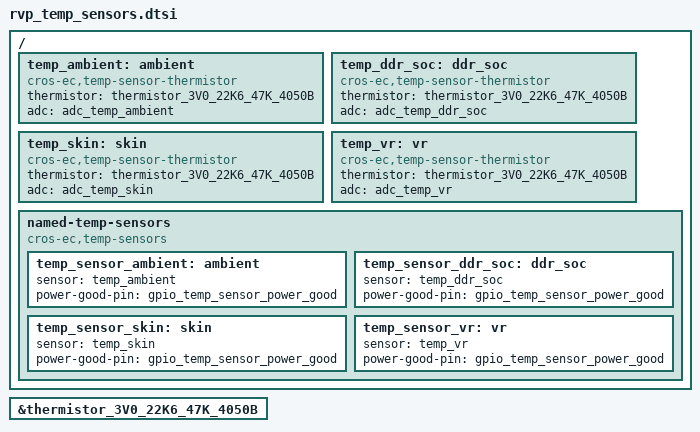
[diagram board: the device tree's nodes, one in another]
/* Copyright 2026 The ChromiumOS Authors
 * Use of this source code is governed by a BSD-style license that can be
 * found in the LICENSE file.
 */

#include <cros/thermistor/thermistor.dtsi>

/ {
        temp_ambient: ambient {
                compatible = "cros-ec,temp-sensor-thermistor";
                thermistor = <&thermistor_3V0_22K6_47K_4050B>;
                adc = <&adc_temp_ambient>;
        };

        temp_ddr_soc: ddr_soc {
                compatible = "cros-ec,temp-sensor-thermistor";
                thermistor = <&thermistor_3V0_22K6_47K_4050B>;
                adc = <&adc_temp_ddr_soc>;
        };
        temp_skin: skin {
                compatible = "cros-ec,temp-sensor-thermistor";
                thermistor = <&thermistor_3V0_22K6_47K_4050B>;
                adc = <&adc_temp_skin>;
        };
        temp_vr: vr {
                compatible = "cros-ec,temp-sensor-thermistor";
                thermistor = <&thermistor_3V0_22K6_47K_4050B>;
                adc = <&adc_temp_vr>;
        };

        named-temp-sensors {
                compatible = "cros-ec,temp-sensors";
                temp_sensor_ambient: ambient {
                        sensor = <&temp_ambient>;
                        power-good-pin = <&gpio_temp_sensor_power_good>;
                };

                temp_sensor_ddr_soc: ddr_soc {
                        sensor = <&temp_ddr_soc>;
                        power-good-pin = <&gpio_temp_sensor_power_good>;
                };
                temp_sensor_skin: skin {
                        sensor = <&temp_skin>;
                        power-good-pin = <&gpio_temp_sensor_power_good>;
                };
                temp_sensor_vr: vr {
                        sensor = <&temp_vr>;
                        power-good-pin = <&gpio_temp_sensor_power_good>;
                };
        };
};

&thermistor_3V0_22K6_47K_4050B {
        status = "okay";
};

